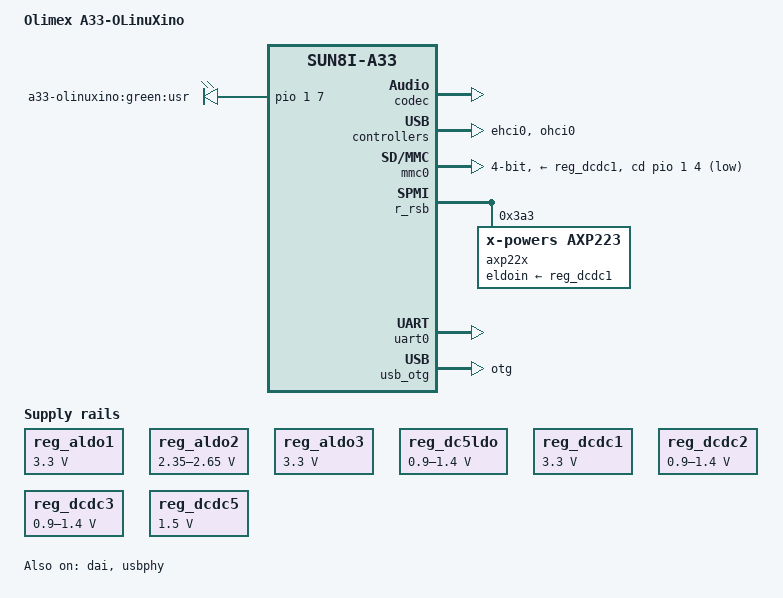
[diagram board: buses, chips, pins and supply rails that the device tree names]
/dts-v1/;
#include "sun8i-a33.dtsi"
#include <dt-bindings/gpio/gpio.h>
#include <dt-bindings/input/input.h>
/ {
	model = "Olimex A33-OLinuXino";
	compatible = "olimex,a33-olinuxino","allwinner,sun8i-a33";
	aliases {
		serial0 = &uart0;
	};
	chosen {
		stdout-path = "serial0:115200n8";
	};
	leds {
		compatible = "gpio-leds";
		led {
			label = "a33-olinuxino:green:usr";
			gpios = <&pio 1 7 GPIO_ACTIVE_HIGH>;
		};
	};
};
&codec {
	status = "okay";
};
&dai {
	status = "okay";
};
&ehci0 {
	status = "okay";
};
&mmc0 {
	vmmc-supply = <&reg_dcdc1>;
	bus-width = <4>;
	cd-gpios = <&pio 1 4 GPIO_ACTIVE_LOW>;  
	status = "okay";
};
&ohci0 {
	status = "okay";
};
&r_rsb {
	status = "okay";
	axp22x: pmic@3a3 {
		compatible = "x-powers,axp223";
		reg = <0x3a3>;
		interrupt-parent = <&r_intc>;
		interrupts = <GIC_SPI 32 IRQ_TYPE_LEVEL_LOW>;
		eldoin-supply = <&reg_dcdc1>;
		x-powers,drive-vbus-en;
	};
};
#include "axp223.dtsi"
&ac_power_supply {
	status = "okay";
};
&battery_power_supply {
	status = "okay";
};
&reg_aldo1 {
	regulator-always-on;
	regulator-min-microvolt = <3300000>;
	regulator-max-microvolt = <3300000>;
	regulator-name = "vcc-io";
};
&reg_aldo2 {
	regulator-always-on;
	regulator-min-microvolt = <2350000>;
	regulator-max-microvolt = <2650000>;
	regulator-name = "vdd-dll";
};
&reg_aldo3 {
	regulator-always-on;
	regulator-min-microvolt = <3300000>;
	regulator-max-microvolt = <3300000>;
	regulator-name = "vcc-avcc";
};
&reg_dc1sw {
	regulator-name = "vcc-lcd";
};
&reg_dc5ldo {
	regulator-always-on;
	regulator-min-microvolt = <900000>;
	regulator-max-microvolt = <1400000>;
	regulator-name = "vdd-cpus";
};
&reg_dcdc1 {
	regulator-always-on;
	regulator-min-microvolt = <3300000>;
	regulator-max-microvolt = <3300000>;
	regulator-name = "vcc-3v3";
};
&reg_dcdc2 {
	regulator-always-on;
	regulator-min-microvolt = <900000>;
	regulator-max-microvolt = <1400000>;
	regulator-name = "vdd-sys";
};
&reg_dcdc3 {
	regulator-always-on;
	regulator-min-microvolt = <900000>;
	regulator-max-microvolt = <1400000>;
	regulator-name = "vdd-cpu";
};
&reg_dcdc5 {
	regulator-always-on;
	regulator-min-microvolt = <1500000>;
	regulator-max-microvolt = <1500000>;
	regulator-name = "vcc-dram";
};
&reg_drivevbus {
	regulator-name = "usb0-vbus";
	status = "okay";
};
&reg_rtc_ldo {
	regulator-name = "vcc-rtc";
};
&simplefb_lcd {
	vcc-lcd-supply = <&reg_dc1sw>;
};
&sound {
	simple-audio-card,widgets = "Microphone", "Microphone Jack",
				    "Headphone", "Headphone Jack";
	simple-audio-card,routing =
		"Left DAC", "DACL",
		"Right DAC", "DACR",
		"HP", "HPCOM",
		"Headphone Jack", "HP",
		"MIC1", "Microphone Jack",
		"Microphone Jack", "MBIAS";
	status = "okay";
};
&uart0 {
	pinctrl-names = "default";
	pinctrl-0 = <&uart0_pb_pins>;
	status = "okay";
};
&usb_otg {
	dr_mode = "otg";
	status = "okay";
};
&usb_power_supply {
	status = "okay";
};
&usbphy {
	usb0_id_det-gpios = <&pio 1 3 GPIO_ACTIVE_HIGH>;  
	usb0_vbus_power-supply = <&usb_power_supply>;
	usb0_vbus-supply = <&reg_drivevbus>;
	status = "okay";
};
